# CEC1712H_N2_SX register map
Vendor: Microchip
Registers are 32-bit, read-write, reset 0x0 unless marked. A register's access mark holds for its fields unless they carry their own. Addresses are absolute, and some are shared; only a register's first bit layout is shown; [hi:lo] are bit positions; {n}, {i} and the like mark numbered series.

## RTOS
0x40007400 CNT
  [31:0] CNTR — This register contains the current value of the RTOS Timer counter. This register should be read as a DWORD. There is no latching mechanism of the upper bytes implemented if the register is accessed as a byte or word. Reading the register with byte or word operations may give incorrect results.
0x40007404 PRLD
  [31:0] PRELOAD — The this register is loaded into the RTOS Timer counter either when the TIMER_START bit is written with a 1, or when the timer counter counts down to 0 and the AUTO_RELOAD bit is 1. This register must be programmed with a new count value before the TIMER_START bit is set to 1. If this register is updated while the counter is operating, the new count value will only take effect if the counter transitions form 1 to 0 while the AUTO_RELOAD bit is set.
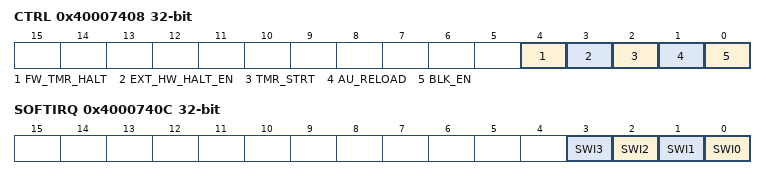
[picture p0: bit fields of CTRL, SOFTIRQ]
0x40007408 CTRL
  [4] FW_TMR_HALT — 1=The timer counter is halted. If the counter was running, clearing this bit will restart the counter from the value at which it halted. 0=The timer counter, if enabled, will continue to run
  [3] EXT_HW_HALT_EN — 1=The timer counter is halted when the external HALT signal is asserted. Counting is always enabled if HALT is de-asserted. 0=The HALT signal does not affect the RTOS Timer
  [2] TMR_STRT — Writing a 1 to this bit will load the timer counter with the RTOS Timer Preload Register and start counting. If the Preload Register is 0, counting will not start and this bit will be cleared to 0. Writing a 0 to this bit will halt the counter and clear its contents to 0. The RTOS timer interrupt will not be generated. This bit is automatically cleared if the AUTO_RELOAD bit is 0 and the timer counter transitions from 1 to 0.
  [1] AU_RELOAD — 1=The the RTOS Timer Preload Register is loaded into the timer counter and the counter is restarted when the counter transitions from 1 to 0. 0=The timer counter halts when it transitions from 1 to 0 and will not restart.
  [0] BLK_EN — 1=RTOS timer counter is enabled. 0=RTOS timer disabled. All register bits are reset to their default state
0x4000740C SOFTIRQ wo
  [n] SWI{n} (n=0..3) — Software Interrupt. A write of a '1' to this bit will generate an SWI interrupt to the EC. Writes of a '0' have no effect. Reads return '0'.

## TFDP
0x40008C00 MSDATA 8-bit
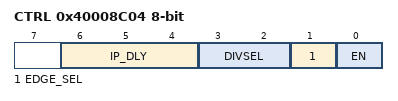
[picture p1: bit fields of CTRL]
0x40008C04 CTRL 8-bit
  [6:4] IP_DLY — Inter-packet Delay. The delay is in terms of TFDP Debug output clocks.
  [3:2] DIVSEL — Clock Divider Select.
  [1] EDGE_SEL — 1= Data is shifted out on the falling edge of the debug clock, 0= Data is shifted out on the rising edge of the debug clock (Default)
  [0] EN — Enable. 1=Clock enabled, 0=Clock is disabled (Default)

## HTM0
0x40009800 PRLD 16-bit
0x40009804 CTRL 16-bit
  [0] CTRL — 1= The Hibernation Timer has a resolution of 0.125s per LSB, which yields a maximum time in excess of 2 hours. 0= The Hibernation Timer has a resolution of 30.5us per LSB, which yields a maximum time of ~2seconds.
0x40009808 CNT 16-bit ro

## HTM1
0x40009820 PRLD 16-bit
0x40009824 CTRL 16-bit
  [0] CTRL — 1= The Hibernation Timer has a resolution of 0.125s per LSB, which yields a maximum time in excess of 2 hours. 0= The Hibernation Timer has a resolution of 30.5us per LSB, which yields a maximum time of ~2seconds.
0x40009828 CNT 16-bit ro

## VBAT
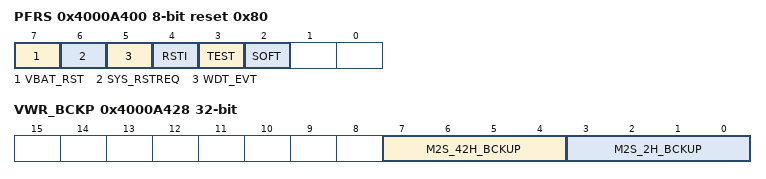
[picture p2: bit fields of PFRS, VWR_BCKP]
0x4000A400 PFRS 8-bit reset 0x80
  [7] VBAT_RST — The VBAT RST bit is set to '1' by hardware when a RESET_VBAT is detected. This is the register default value. To clear VBAT RST EC firmware must write a '1' to this bit; writing a '0' to VBAT RST has no affect.(R/WC)
  [6] SYS_RSTREQ — This bit is set to '1b' if a RESET_SYS was triggered by an ARM SYSRESETREQ event. This bit is cleared to '0b' when written with a '1b'; writes of a '0b' have no effect. (R/WC)
  [5] WDT_EVT — This bit is set to '1b' if a RESET_SYS was triggered by a Watchdog Timer event. This bit is cleared to '0b' when written with a '1b'; writes of a '0b' have no effect. (R/WC)
  [4] RSTI — This bit is set to '1b' if a RESET_SYS was triggered by a low signal on the RESETI# input pin. This bit is cleared to '0b' when written with a '1b'; writes of a '0b' have no effect. (R/WC)
  [3] TEST
  [2] SOFT — This bit is set to '1b' if a was triggered by an assertion of the SOFT_SYS_RESET bit in the System Reset Register. This bit is cleared to '0b' when written with a '1b'; writes of a '0b' have no effect. (R/WC)
0x4000A408 CLK32_EN
  [1] EXT_32K — This bit selects the source for the 32KHz clock domain. 1=The 32KHZ_IN VTR-powered pin is used as a source for the 32KHz clock domain. If an activity detector does not detect a clock on the selected source, the always-on 32KHz internal clock source is automatically selected. 0=The always-on32Khz clock source is used as the source for the 32KHz clock domain.
0x4000A40C SYS_SHDN
  [0] DIS — This bit controls the System Shutdown. 0 = Enable System Shutdown (SYS_SHDN#). 1 = Disable System Shutdown (SYS_SHDN#).
0x4000A420 MCNT_LO
  [31:0] CNTR — Read-only register that increments by 1 every time it is read. It is reset to 0 on a VBAT Power On Reset.
0x4000A424 MCNT_HI
  [31:0] CNTR — Thirty-two bit read/write register. If software sets this register to an incrementing value, based on an external non-volatile store, this register may be combined with the Monotonic Counter Register to form a 64-bit monotonic counter.
0x4000A428 VWR_BCKP
  [7:4] M2S_42H_BCKUP — The Boot ROM firmware will copy this field into the SRC3 to SRC0 bits of the Master-to-Slave Virtual Wire Register that corresponds to Virtual Wire Index 42h on a RESET_SYS. If software always saves the state of the Index 2h SRC bits on the falling edge of the SUSWARN# virtual wire, the state of the four SRC bits will be synchronized to the state of the four bits in the core logic.
  [3:0] M2S_2H_BCKUP — The Boot ROM firmware will copy this field into the SRC3 to SRC0 bits of the Master-to-Slave Virtual Wire Register that corresponds to Virtual Wire Index 2h on a RESET_SYS. If software always saves the state of the Index 2h SRC bits on the falling edge of the SUSWARN# virtual wire, the state of the four SRC bits will be synchronized to the state of the four bits in the core logic.
